# AT32F421xx register map
Vendor: Keil; Series: AT32F421; File version: 1.0
CPU: CM4 r0p1, little endian, no MPU, FPU, 4 interrupt priority bits
Registers are 32-bit, read-write, reset 0x0 unless marked. A register's access mark holds for its fields unless they carry their own. Offsets are from the block's base; [hi:lo] are bit positions.

## TMR15 — General-purpose-timers
Base 0x40014000
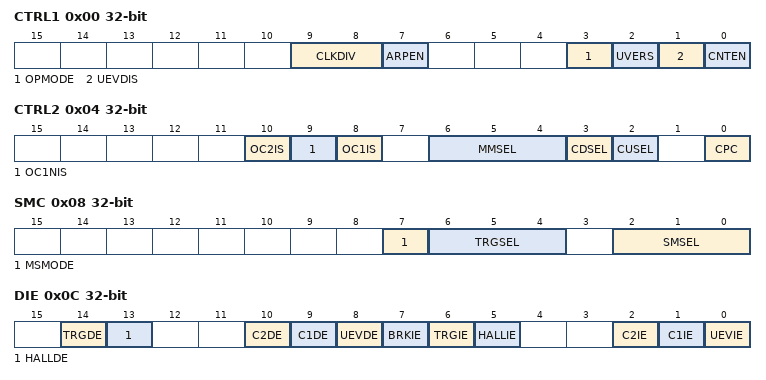
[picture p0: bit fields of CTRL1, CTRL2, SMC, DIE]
0x00 CTRL1 — control register 1
  [9:8] CLKDIV — Clock division
  [7] ARPEN — Auto-reload preload enable
  [3] OPMODE — One-pulse mode
  [2] UVERS — Update request source
  [1] UEVDIS — Update disable
  [0] CNTEN — Counter enable
0x04 CTRL2 — control register 2
  [10] OC2IS — Output Idle state 2
  [9] OC1NIS — Output Idle state 1
  [8] OC1IS — Output Idle state 1
  [6:4] MMSEL — Master mode selection
  [3] CDSEL — Capture/compare DMA selection
  [2] CUSEL — Capture/compare control update selection
  [0] CPC — Capture/compare preloaded control
0x08 SMC — slave mode control register
  [7] MSMODE — Master/Slave mode
  [6:4] TRGSEL — Trigger selection
  [2:0] SMSEL — Slave mode selection
0x0C DIE — DMA/Interrupt enable register
  [14] TRGDE — Trigger DMA request enable
  [13] HALLDE — HALL DMA request enable
  [10] C2DE — Capture/Compare 2 DMA request enable
  [9] C1DE — Capture/Compare 1 DMA request enable
  [8] UEVDE — Update DMA request enable
  [7] BRKIE — Break interrupt enable
  [6] TRGIE — Trigger interrupt enable
  [5] HALLIE — hall interrupt enable
  [2] C2IE — Capture/Compare 2 interrupt enable
  [1] C1IE — Capture/Compare 1 interrupt enable
  [0] UEVIE — Update interrupt enable
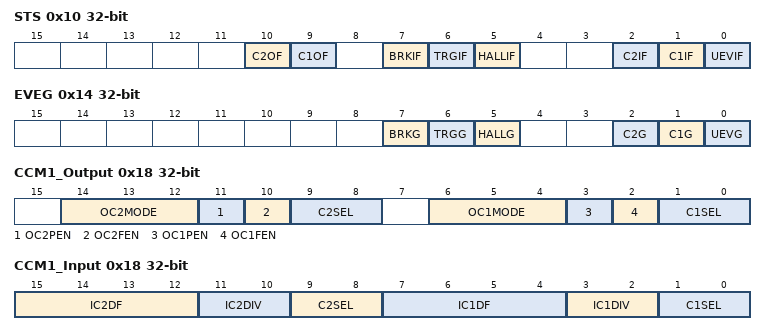
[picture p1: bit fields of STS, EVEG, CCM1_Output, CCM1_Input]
0x10 STS — status register
  [10] C2OF — Capture/compare 2 overcapture flag
  [9] C1OF — Capture/Compare 1 overcapture flag
  [7] BRKIF — Break interrupt flag
  [6] TRGIF — Trigger interrupt flag
  [5] HALLIF — HALL interrupt flag
  [2] C2IF — Capture/Compare 2 interrupt flag
  [1] C1IF — Capture/compare 1 interrupt flag
  [0] UEVIF — Update interrupt flag
0x14 EVEG wo — event generation register
  [7] BRKG — Break generation
  [6] TRGG — Trigger generation
  [5] HALLG — Capture/Compare control update generation
  [2] C2G — Capture/compare 2 generation
  [1] C1G — Capture/compare 1 generation
  [0] UEVG — Update generation
0x18 CCM1_Output — capture/compare mode register (output mode)
  [14:12] OC2MODE — Output Compare 2 mode
  [11] OC2PEN — Output Compare 2 preload enable
  [10] OC2FEN — Output Compare 2 fast enable
  [9:8] C2SEL — Capture/Compare 2 selection
  [6:4] OC1MODE — Output Compare 1 mode
  [3] OC1PEN — Output Compare 1 preload enable
  [2] OC1FEN — Output Compare 1 fast enable
  [1:0] C1SEL — Capture/Compare 1 selection
0x18 CCM1_Input (alternate view of CCM1_Output) — capture/compare mode register 1 (input mode)
  [15:12] IC2DF — Input capture 2 filter
  [11:10] IC2DIV — Input capture 2 prescaler
  [9:8] C2SEL — Capture/Compare 2 selection
  [7:4] IC1DF — Input capture 1 filter
  [3:2] IC1DIV — Input capture 1 prescaler
  [1:0] C1SEL — Capture/Compare 1 selection
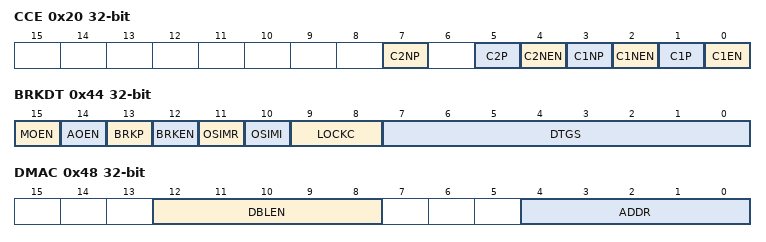
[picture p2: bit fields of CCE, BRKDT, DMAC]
0x20 CCE — capture/compare enable register
  [7] C2NP — Capture/Compare 2 output Polarity
  [5] C2P — Capture/Compare 2 output Polarity
  [4] C2NEN — Capture/Compare 2 output enable
  [3] C1NP — Capture/Compare 1 output Polarity
  [2] C1NEN — Capture/Compare 1 complementary output enable
  [1] C1P — Capture/Compare 1 output Polarity
  [0] C1EN — Capture/Compare 1 output enable
0x24 CNT — counter
  [15:0] CNT — counter value
0x28 DIV — Clock divider
  [15:0] DIV — Prescaler value
0x2C AR — auto-reload register
  [15:0] AR — Auto-reload value
0x30 RC — repetition counter register
  [7:0] RC — Repetition counter value
0x34 CC1 — capture/compare register 1
  [15:0] CC1 — Capture/Compare 1 value
0x38 CC2 — capture/compare register 2
  [15:0] CC2 — Capture/Compare 2 value
0x44 BRKDT — break and dead-time register
  [15] MOEN — Main output enable
  [14] AOEN — Automatic output enable
  [13] BRKP — Break polarity
  [12] BRKEN — Break enable
  [11] OSIMR — Off-state selection for Run mode
  [10] OSIMI — Off-state selection for Idle mode
  [9:8] LOCKC — Lock configuration
  [7:0] DTGS — Dead-time generator setup
0x48 DMAC — DMA control register
  [12:8] DBLEN — DMA burst length
  [4:0] ADDR — DMA base address
0x4C DMABA — DMA address for full transfer
  [15:0] DMABA — DMA register for burst accesses
